# RP2040 register map
Vendor: Raspberry Pi; File version: 2025.06.15
CPU: CM0PLUS r0p1, little endian, 2 interrupt priority bits
Registers are 32-bit, read-write, no defined reset value unless marked. A register's access mark holds for its fields unless they carry their own. Offsets are from the block's base; [hi:lo] are bit positions; {n}, {i} and the like mark numbered series; 'fields as' and 'values as' point back to an identical list.

## IO_QSPI
Base 0x40018000
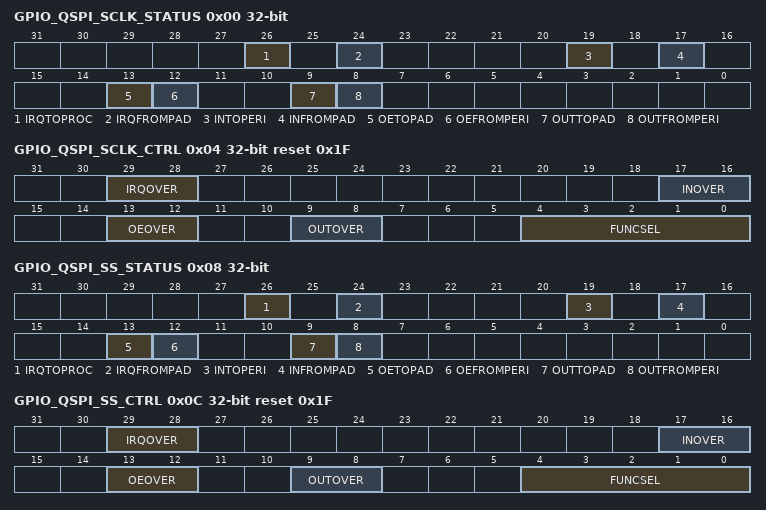
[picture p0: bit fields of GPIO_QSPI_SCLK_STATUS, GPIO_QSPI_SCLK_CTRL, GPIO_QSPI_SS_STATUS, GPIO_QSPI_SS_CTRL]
0x00 GPIO_QSPI_SCLK_STATUS — GPIO status
  [26] IRQTOPROC ro — interrupt to processors, after override is applied
  [24] IRQFROMPAD ro — interrupt from pad before override is applied
  [19] INTOPERI ro — input signal to peripheral, after override is applied
  [17] INFROMPAD ro — input signal from pad, before override is applied
  [13] OETOPAD ro — output enable to pad after register override is applied
  [12] OEFROMPERI ro — output enable from selected peripheral, before register override is applied
  [9] OUTTOPAD ro — output signal to pad after register override is applied
  [8] OUTFROMPERI ro — output signal from selected peripheral, before register override is applied
0x04 GPIO_QSPI_SCLK_CTRL reset 0x1F (reset mask 0x0) — GPIO control including function select and overrides.
  [29:28] IRQOVER
    0=NORMAL (don't invert the interrupt); 1=INVERT (invert the interrupt); 2=LOW (drive interrupt low); 3=HIGH (drive interrupt high)
  [17:16] INOVER
    0=NORMAL (don't invert the peri input); 1=INVERT (invert the peri input); 2=LOW (drive peri input low); 3=HIGH (drive peri input high)
  [13:12] OEOVER
    0=NORMAL (drive output enable from peripheral signal selected by funcsel); 1=INVERT (drive output enable from inverse of peripheral signal selected by funcsel); 2=DISABLE (disable output); 3=ENABLE (enable output)
  [9:8] OUTOVER
    0=NORMAL (drive output from peripheral signal selected by funcsel); 1=INVERT (drive output from inverse of peripheral signal selected by funcsel); 2=LOW (drive output low); 3=HIGH (drive output high)
  [4:0] FUNCSEL — 0-31 -> selects pin function according to the gpio table 31 == NULL
    0=xip_sclk (None); 31=null (None); 5=sio_30 (None)
0x08 GPIO_QSPI_SS_STATUS — GPIO status
  fields as GPIO_QSPI_SCLK_STATUS
0x0C GPIO_QSPI_SS_CTRL reset 0x1F (reset mask 0x0) — GPIO control including function select and overrides.
  [29:28] IRQOVER
    values as GPIO_QSPI_SCLK_CTRL.IRQOVER
  [17:16] INOVER
    values as GPIO_QSPI_SCLK_CTRL.INOVER
  [13:12] OEOVER
    values as GPIO_QSPI_SCLK_CTRL.OEOVER
  [9:8] OUTOVER
    values as GPIO_QSPI_SCLK_CTRL.OUTOVER
  [4:0] FUNCSEL — 0-31 -> selects pin function according to the gpio table 31 == NULL
    0=xip_ss_n (None); 31=null (None); 5=sio_31 (None)
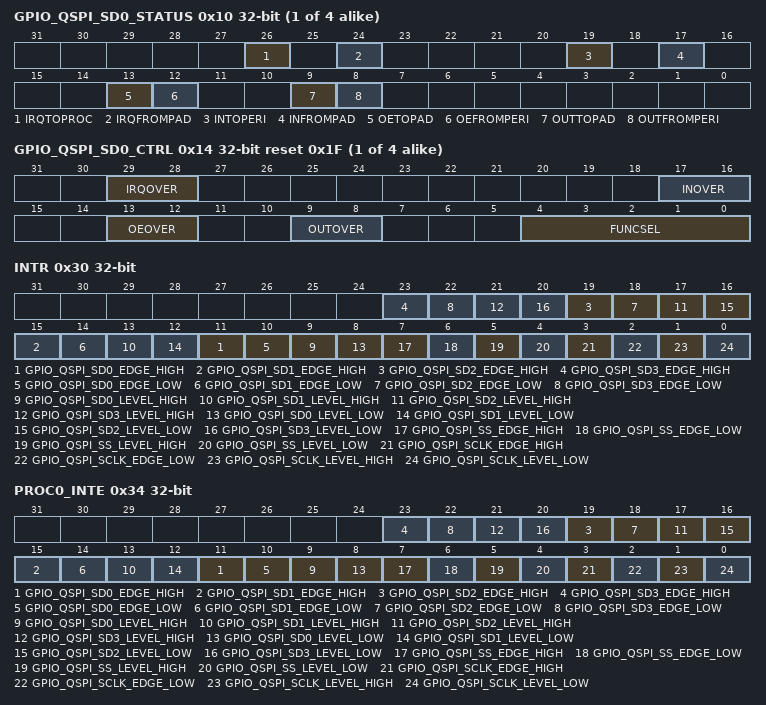
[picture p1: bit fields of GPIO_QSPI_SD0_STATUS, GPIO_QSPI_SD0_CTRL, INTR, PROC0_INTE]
{0x10+8i} GPIO_QSPI_SD{i}_STATUS (i=0..3) — GPIO status
  fields as GPIO_QSPI_SCLK_STATUS
{0x14+8i} GPIO_QSPI_SD{i}_CTRL reset 0x1F (reset mask 0x0) (i=0..3) — GPIO control including function select and overrides.
  [29:28] IRQOVER
    values as GPIO_QSPI_SCLK_CTRL.IRQOVER
  [17:16] INOVER
    values as GPIO_QSPI_SCLK_CTRL.INOVER
  [13:12] OEOVER
    values as GPIO_QSPI_SCLK_CTRL.OEOVER
  [9:8] OUTOVER
    values as GPIO_QSPI_SCLK_CTRL.OUTOVER
  [4:0] FUNCSEL — 0-31 -> selects pin function according to the gpio table 31 == NULL
    0=xip_sd{i} (None); 31=null (None); 5=sio_{i+32} (None)
0x30 INTR — Raw Interrupts
  [4n+11] GPIO_QSPI_SD{n}_EDGE_HIGH write-1-clears (n=0..3), [4n+10] GPIO_QSPI_SD{n}_EDGE_LOW write-1-clears (n=0..3), [4n+9] GPIO_QSPI_SD{n}_LEVEL_HIGH ro (n=0..3), [4n+8] GPIO_QSPI_SD{n}_LEVEL_LOW ro (n=0..3), [7] GPIO_QSPI_SS_EDGE_HIGH write-1-clears, [6] GPIO_QSPI_SS_EDGE_LOW write-1-clears, [5] GPIO_QSPI_SS_LEVEL_HIGH ro, [4] GPIO_QSPI_SS_LEVEL_LOW ro, [3] GPIO_QSPI_SCLK_EDGE_HIGH write-1-clears, [2] GPIO_QSPI_SCLK_EDGE_LOW write-1-clears, [1] GPIO_QSPI_SCLK_LEVEL_HIGH ro, [0] GPIO_QSPI_SCLK_LEVEL_LOW ro
0x34 PROC0_INTE — Interrupt Enable for proc0
  [4n+11] GPIO_QSPI_SD{n}_EDGE_HIGH (n=0..3), [4n+10] GPIO_QSPI_SD{n}_EDGE_LOW (n=0..3), [4n+9] GPIO_QSPI_SD{n}_LEVEL_HIGH (n=0..3), [4n+8] GPIO_QSPI_SD{n}_LEVEL_LOW (n=0..3), [7] GPIO_QSPI_SS_EDGE_HIGH, [6] GPIO_QSPI_SS_EDGE_LOW, [5] GPIO_QSPI_SS_LEVEL_HIGH, [4] GPIO_QSPI_SS_LEVEL_LOW, [3] GPIO_QSPI_SCLK_EDGE_HIGH, [2] GPIO_QSPI_SCLK_EDGE_LOW, [1] GPIO_QSPI_SCLK_LEVEL_HIGH, [0] GPIO_QSPI_SCLK_LEVEL_LOW
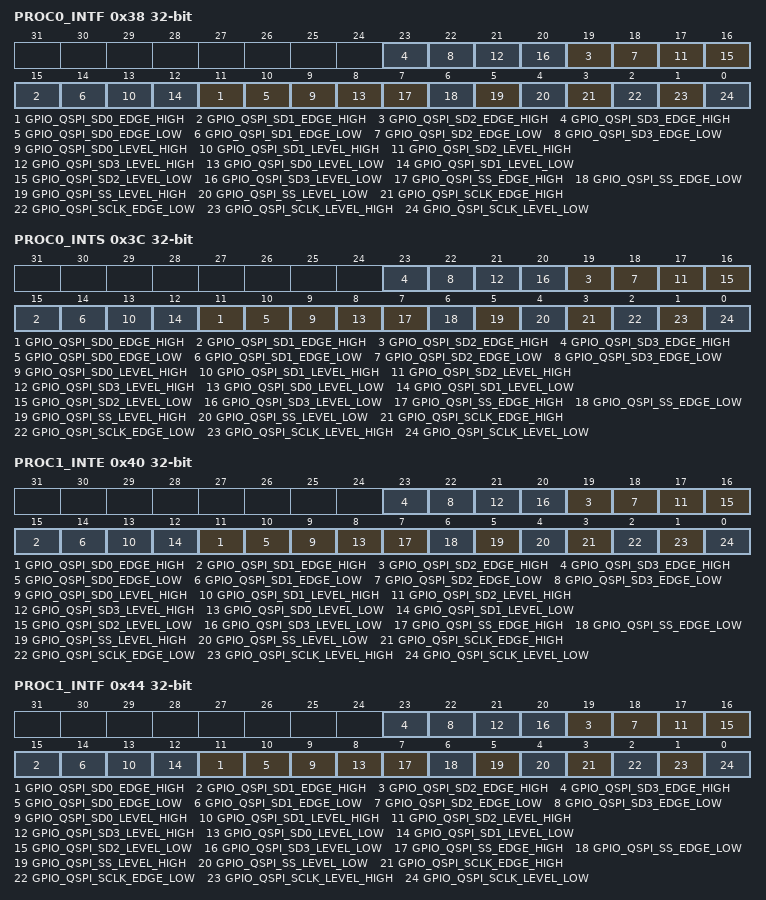
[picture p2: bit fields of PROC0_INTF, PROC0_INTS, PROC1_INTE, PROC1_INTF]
0x38 PROC0_INTF — Interrupt Force for proc0
  fields as PROC0_INTE
0x3C PROC0_INTS — Interrupt status after masking & forcing for proc0
  [4n+11] GPIO_QSPI_SD{n}_EDGE_HIGH ro (n=0..3), [4n+10] GPIO_QSPI_SD{n}_EDGE_LOW ro (n=0..3), [4n+9] GPIO_QSPI_SD{n}_LEVEL_HIGH ro (n=0..3), [4n+8] GPIO_QSPI_SD{n}_LEVEL_LOW ro (n=0..3), [7] GPIO_QSPI_SS_EDGE_HIGH ro, [6] GPIO_QSPI_SS_EDGE_LOW ro, [5] GPIO_QSPI_SS_LEVEL_HIGH ro, [4] GPIO_QSPI_SS_LEVEL_LOW ro, [3] GPIO_QSPI_SCLK_EDGE_HIGH ro, [2] GPIO_QSPI_SCLK_EDGE_LOW ro, [1] GPIO_QSPI_SCLK_LEVEL_HIGH ro, [0] GPIO_QSPI_SCLK_LEVEL_LOW ro
0x40 PROC1_INTE — Interrupt Enable for proc1
  fields as PROC0_INTE
0x44 PROC1_INTF — Interrupt Force for proc1
  fields as PROC0_INTE
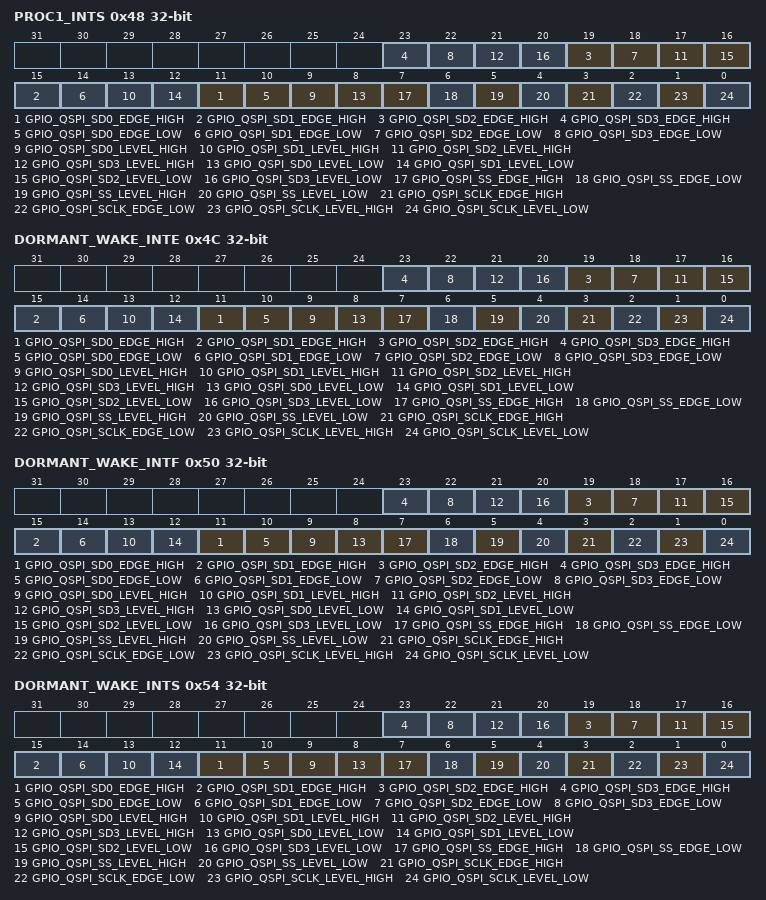
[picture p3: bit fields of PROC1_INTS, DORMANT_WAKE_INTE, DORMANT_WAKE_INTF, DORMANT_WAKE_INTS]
0x48 PROC1_INTS — Interrupt status after masking & forcing for proc1
  fields as PROC0_INTS
0x4C DORMANT_WAKE_INTE — Interrupt Enable for dormant_wake
  fields as PROC0_INTE
0x50 DORMANT_WAKE_INTF — Interrupt Force for dormant_wake
  fields as PROC0_INTE
0x54 DORMANT_WAKE_INTS — Interrupt status after masking & forcing for dormant_wake
  fields as PROC0_INTS
